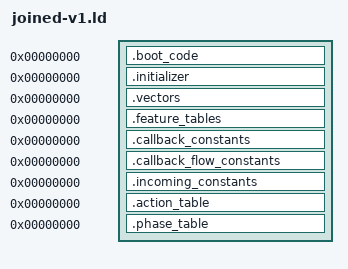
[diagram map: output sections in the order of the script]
OUTPUT_ARCH(riscv)
SECTIONS
{
 .boot_code 0 : SUBALIGN(2) { *(.boot_code)
  *(.text.tsl9_control_gates_provider_81ee)
  *(.text.tsl9_control_gates_provider_a658)
  *(.text.tsl9_control_gates_provider_a9de)
  *(.text.tsl9_record_dispatch_provider_cd6a)
  *(.text.tsl9_control_gates_block_cd78)
  *(.text.tsl9_control_gates_block_cd84)
  *(.text.tsl9_control_gates_block_cd90)
  *(.text.tsl9_control_gates_block_cd96)
  *(.text.tsl9_control_gates_block_cd98)
  *(.text.tsl9_control_gates_block_cd9e)
  *(.text.tsl9_control_gates_block_cda6)
  *(.text.tsl9_control_gates_block_cdb4)
  *(.text.tsl9_control_gates_block_cdb6)
  *(.text.tsl9_control_gates_block_cdbc)
  *(.text.tsl9_control_gates_block_cdc6)
  *(.text.tsl9_control_gates_block_cdce)
  *(.text.tsl9_control_gates_block_cdd8)
  *(.text.tsl9_control_gates_block_cddc)
  *(.text.tsl9_control_gates_block_cde8)
  *(.text.tsl9_control_gates_block_cdec)
  *(.text.tsl9_control_gates_block_cdf2)
  *(.text.tsl9_control_gates_block_cdfc)
  *(.text.tsl9_control_gates_block_cdfe)
  *(.text.tsl9_control_gates_block_ce08)
  *(.text.tsl9_control_gates_block_ce0c)
  *(.text.tsl9_control_gates_block_ce12)
  *(.text.tsl9_control_gates_block_ce16)
  *(.text.tsl9_control_gates_block_ce1a)
  *(.text.tsl9_control_gates_block_ce1e)
  *(.text.tsl9_control_gates_block_ce20)
  *(.text.tsl9_control_gates_block_ce24)
  *(.text.tsl9_control_gates_block_ce26)
  *(.text.tsl9_control_gates_block_ce2a)
  *(.text.tsl9_control_gates_block_ce2e)
  *(.text.tsl9_control_gates_block_ce30)
  *(.text.tsl9_control_gates_block_ce34)
  *(.text.tsl9_control_gates_block_ce38)
  *(.text.tsl9_control_gates_block_ce3c)
  *(.text.tsl9_control_gates_block_ce48)
  *(.text.tsl9_control_gates_block_ce4c)
  *(.text.tsl9_control_gates_block_ce52)
  *(.text.tsl9_control_gates_block_ce54)
  *(.text.tsl9_control_gates_block_ce58)
  *(.text.tsl9_control_gates_block_ce5c)
  *(.text.tsl9_control_gates_block_ce62)
  *(.text.tsl9_control_gates_block_ce64)
  *(.text.tsl9_control_gates_block_ce66)
  *(.text.tsl9_control_gates_block_ce68)
  *(.text.tsl9_control_gates_block_ce6a)
  *(.text.tsl9_control_gates_block_ce6e)
  *(.text.tsl9_control_gates_block_ce70)
  *(.text.tsl9_control_gates_block_ce72)
  *(.text.tsl9_control_gates_block_ce74)
  *(.text.tsl9_control_gates_block_ce7a)
  *(.text.tsl9_control_gates_block_ce7e)
  *(.text.tsl9_control_gates_block_ce82)
  *(.text.tsl9_control_gates_block_ce84)
  *(.text.tsl9_record_dispatch_provider_d07c)
  *(.text.tsl9_control_gates_block_d088)
  *(.text.tsl9_control_gates_block_d094)
  *(.text.tsl9_control_gates_block_d09a)
  *(.text.tsl9_control_gates_block_d0a0)
  *(.text.tsl9_control_gates_block_d0a6)
  *(.text.tsl9_control_gates_block_d0ac)
  *(.text.tsl9_control_gates_block_d0b2)
  *(.text.tsl9_control_gates_block_d0bc)
  *(.text.tsl9_control_gates_block_d0c4)
  *(.text.tsl9_control_gates_block_d0cc)
  *(.text.tsl9_control_gates_block_d0d4)
  *(.text.tsl9_control_gates_block_d0de)
  *(.text.tsl9_control_gates_block_d0ec)
  *(.text.tsl9_main_services_provider_d0ee)
  *(.text.tsl9_control_gates_provider_fb1e)
  *(.text.tsl9_control_gates_block_fb26)
  *(.text.tsl9_control_gates_block_fb2c)
  *(.text.tsl9_control_gates_block_fb32)
  *(.text.tsl9_control_gates_block_fb4e)
  *(.text.tsl9_control_gates_provider_fb5e)
  *(.text.tsl9_control_gates_block_fb66)
  *(.text.tsl9_control_gates_block_fb6c)
  *(.text.tsl9_control_gates_block_fb8e)
  *(.text.tsl9_record_dispatch_provider_fd6a)
  *(.text.tsl9_control_gates_block_fd70)
  *(.text.tsl9_control_gates_block_fd76)
  *(.text.tsl9_control_gates_block_fd7e)
  *(.text.tsl9_control_gates_block_fd80)
  *(.text.tsl9_control_gates_block_fd86)
  *(.text.tsl9_control_gates_block_fd96)
  *(.text.tsl9_control_gates_block_fd9a)
  *(.text.tsl9_record_dispatch_provider_fdf6)
  *(.text.tsl9_control_gates_block_fe02)
  *(.text.tsl9_control_gates_block_fe06)
  *(.text.tsl9_control_gates_provider_fe6a)
  *(.text.tsl9_control_gates_block_fe7a)
  *(.text.tsl9_control_gates_block_fe8a)
  *(.text.tsl9_control_gates_block_fe8c)
  *(.text.tsl9_control_gates_block_fe8e)
  *(.text.tsl9_control_gates_block_fe92)
  *(.text.tsl9_control_gates_block_fe9c)
  *(.text.tsl9_control_gates_block_fea2)
  *(.text.tsl9_control_gates_block_fea4)
  *(.text.tsl9_control_gates_block_fea8)
  *(.text.tsl9_control_gates_block_feb4)
  *(.text.tsl9_control_gates_block_febe)
  *(.text.tsl9_control_gates_block_fece)
  *(.text.tsl9_control_gates_block_feda)
  *(.text.tsl9_control_gates_block_fee4)
  *(.text.tsl9_control_gates_block_feee)
  *(.text.tsl9_control_gates_block_fef0)
  *(.text.tsl9_control_gates_block_fef6)
  *(.text.tsl9_control_gates_block_fefa)
  *(.text.tsl9_control_gates_block_fefc)
  *(.text.tsl9_control_gates_block_ff00)
  *(.text.tsl9_control_gates_block_ff10)
  *(.text.tsl9_control_gates_block_ff16)
  *(.text.tsl9_control_gates_block_ff1c)
  *(.text.tsl9_control_gates_block_ff22)
  *(.text.tsl9_control_gates_block_ff2e)
  *(.text.tsl9_control_gates_block_ff3a)
  *(.text.tsl9_control_gates_block_ff42)
  *(.text.tsl9_control_gates_provider_10022)
  *(.text.tsl9_control_gates_block_1002a)
  *(.text.tsl9_control_gates_block_1002c)
 }
 .initializer 0 : SUBALIGN(4) { *(.initializer) }
 .vectors 0 : SUBALIGN(4) { *(.vectors) }
 .feature_tables 0 : SUBALIGN(4) { *(.feature_tables) }
 .callback_constants 0 : SUBALIGN(4) { *(.callback_constants) }
 .callback_flow_constants 0 : SUBALIGN(4) { *(.callback_flow_constants) }
 .incoming_constants 0 : SUBALIGN(4) { *(.incoming_constants) }
 .action_table 0 : SUBALIGN(4) { *(.action_table) }
 .phase_table 0 : SUBALIGN(4) { *(.phase_table) }
 /DISCARD/ : { *(.comment) *(.riscv.attributes) *(.llvm_addrsig) }
}
